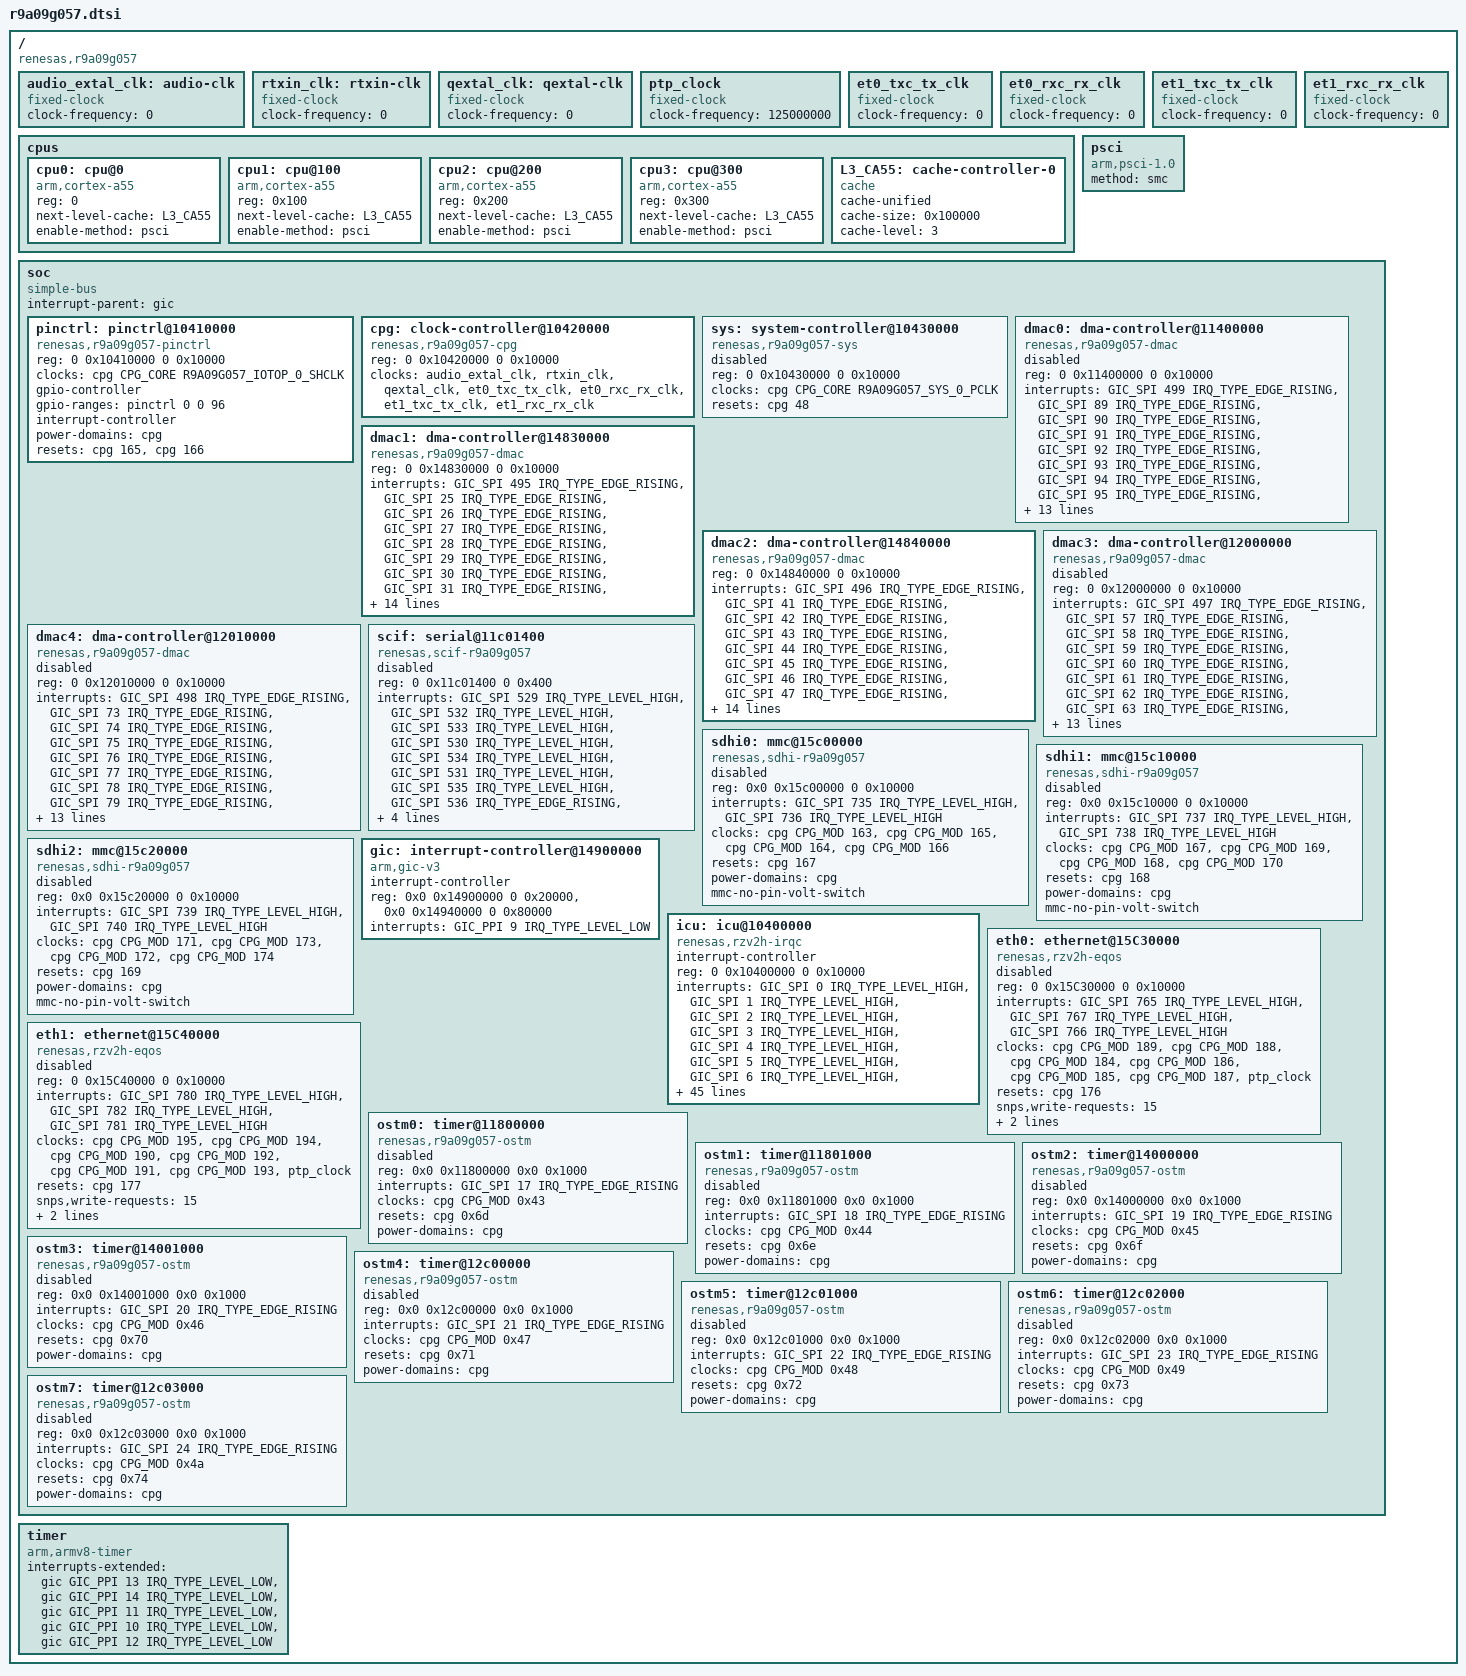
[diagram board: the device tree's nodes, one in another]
// SPDX-License-Identifier: (GPL-2.0-only OR BSD-2-Clause)
/*
 * Device Tree Source for the RZ/V2H SoC
 *
 * Copyright (C) 2024 Renesas Electronics Corp.
 */

#include <dt-bindings/clock/renesas,r9a09g057-cpg.h>
#include <dt-bindings/interrupt-controller/arm-gic.h>

/ {
	compatible = "renesas,r9a09g057";
	#address-cells = <2>;
	#size-cells = <2>;

	audio_extal_clk: audio-clk {
		compatible = "fixed-clock";
		#clock-cells = <0>;
		/* This value must be overridden by the board */
		clock-frequency = <0>;
	};

	rtxin_clk: rtxin-clk {
		compatible = "fixed-clock";
		#clock-cells = <0>;
		/* This value must be overridden by the board */
		clock-frequency = <0>;
	};

	qextal_clk: qextal-clk {
		compatible = "fixed-clock";
		#clock-cells = <0>;
		/* This value must be overridden by the board */
		clock-frequency = <0>;
	};

	/* ptp_clock input */
	ptp_clock: ptp_clock {
		compatible = "fixed-clock";
		#clock-cells = <0>;
		/* This value must be overridden by the board */
		clock-frequency = <125000000>;
	};

	/* et0_txc_tx_clk clock input */
	et0_txc_tx_clk: et0_txc_tx_clk {
		compatible = "fixed-clock";
		#clock-cells = <0>;
		/* This value must be overridden by the board */
		clock-frequency = <0>;
	};

	/* et0_rxc_rx_clk clock input */
	et0_rxc_rx_clk: et0_rxc_rx_clk {
		compatible = "fixed-clock";
		#clock-cells = <0>;
		/* This value must be overridden by the board */
		clock-frequency = <0>;
	};

	/* et1_txc_tx_clk clock input */
	et1_txc_tx_clk: et1_txc_tx_clk {
		compatible = "fixed-clock";
		#clock-cells = <0>;
		/* This value must be overridden by the board */
		clock-frequency = <0>;
	};

	/* et1_rxc_rx_clk clock input */
	et1_rxc_rx_clk: et1_rxc_rx_clk {
		compatible = "fixed-clock";
		#clock-cells = <0>;
		/* This value must be overridden by the board */
		clock-frequency = <0>;
	};

	cpus {
		#address-cells = <1>;
		#size-cells = <0>;

		cpu0: cpu@0 {
			compatible = "arm,cortex-a55";
			reg = <0>;
			device_type = "cpu";
			next-level-cache = <&L3_CA55>;
			enable-method = "psci";
		};

		cpu1: cpu@100 {
			compatible = "arm,cortex-a55";
			reg = <0x100>;
			device_type = "cpu";
			next-level-cache = <&L3_CA55>;
			enable-method = "psci";
		};

		cpu2: cpu@200 {
			compatible = "arm,cortex-a55";
			reg = <0x200>;
			device_type = "cpu";
			next-level-cache = <&L3_CA55>;
			enable-method = "psci";
		};

		cpu3: cpu@300 {
			compatible = "arm,cortex-a55";
			reg = <0x300>;
			device_type = "cpu";
			next-level-cache = <&L3_CA55>;
			enable-method = "psci";
		};

		L3_CA55: cache-controller-0 {
			compatible = "cache";
			cache-unified;
			cache-size = <0x100000>;
			cache-level = <3>;
		};
	};

	psci {
		compatible = "arm,psci-1.0", "arm,psci-0.2";
		method = "smc";
	};

	soc: soc {
		compatible = "simple-bus";
		interrupt-parent = <&gic>;
		#address-cells = <2>;
		#size-cells = <2>;
		ranges;

		pinctrl: pinctrl@10410000 {
			compatible = "renesas,r9a09g057-pinctrl";
			reg = <0 0x10410000 0 0x10000>;
			clocks = <&cpg CPG_CORE R9A09G057_IOTOP_0_SHCLK>;
			gpio-controller;
			#gpio-cells = <2>;
			gpio-ranges = <&pinctrl 0 0 96>;
			#interrupt-cells = <2>;
			interrupt-controller;
			power-domains = <&cpg>;
			resets = <&cpg 165>, <&cpg 166>;
		};

		cpg: clock-controller@10420000 {
			compatible = "renesas,r9a09g057-cpg";
			reg = <0 0x10420000 0 0x10000>;
			clocks = <&audio_extal_clk>, <&rtxin_clk>, <&qextal_clk>,
				 <&et0_txc_tx_clk>, <&et0_rxc_rx_clk>,
				 <&et1_txc_tx_clk>, <&et1_rxc_rx_clk>;
			clock-names = "audio_extal", "rtxin", "qextal",
				      "et0_txc_tx_clk", "et0_rxc_rx_clk",
				      "et1_txc_tx_clk", "et1_rxc_rx_clk";
			#clock-cells = <2>;
			#reset-cells = <1>;
			#power-domain-cells = <0>;
		};

		sys: system-controller@10430000 {
			compatible = "renesas,r9a09g057-sys";
			reg = <0 0x10430000 0 0x10000>;
			clocks = <&cpg CPG_CORE R9A09G057_SYS_0_PCLK>;
			resets = <&cpg 48>;
			status = "disabled";
		};

		dmac0: dma-controller@11400000 {
			compatible = "renesas,r9a09g057-dmac";
			reg = <0 0x11400000 0 0x10000>;
			interrupts = <GIC_SPI 499 IRQ_TYPE_EDGE_RISING>,
				     <GIC_SPI 89 IRQ_TYPE_EDGE_RISING>,
				     <GIC_SPI 90 IRQ_TYPE_EDGE_RISING>,
				     <GIC_SPI 91 IRQ_TYPE_EDGE_RISING>,
				     <GIC_SPI 92 IRQ_TYPE_EDGE_RISING>,
				     <GIC_SPI 93 IRQ_TYPE_EDGE_RISING>,
				     <GIC_SPI 94 IRQ_TYPE_EDGE_RISING>,
				     <GIC_SPI 95 IRQ_TYPE_EDGE_RISING>,
				     <GIC_SPI 96 IRQ_TYPE_EDGE_RISING>,
				     <GIC_SPI 97 IRQ_TYPE_EDGE_RISING>,
				     <GIC_SPI 98 IRQ_TYPE_EDGE_RISING>,
				     <GIC_SPI 99 IRQ_TYPE_EDGE_RISING>,
				     <GIC_SPI 100 IRQ_TYPE_EDGE_RISING>,
				     <GIC_SPI 101 IRQ_TYPE_EDGE_RISING>,
				     <GIC_SPI 102 IRQ_TYPE_EDGE_RISING>,
				     <GIC_SPI 103 IRQ_TYPE_EDGE_RISING>,
				     <GIC_SPI 104 IRQ_TYPE_EDGE_RISING>;
			interrupt-names = "error",
					  "ch0", "ch1", "ch2", "ch3",
					  "ch4", "ch5", "ch6", "ch7",
					  "ch8", "ch9", "ch10", "ch11",
					  "ch12", "ch13", "ch14", "ch15";
			clocks = <&cpg CPG_MOD 0>;
			power-domains = <&cpg>;
			resets = <&cpg 49>;
			#dma-cells = <1>;
			dma-channels = <16>;
			status = "disabled";
		};

		dmac1: dma-controller@14830000 {
			compatible = "renesas,r9a09g057-dmac";
			reg = <0 0x14830000 0 0x10000>;
			interrupts = <GIC_SPI 495 IRQ_TYPE_EDGE_RISING>,
				     <GIC_SPI 25 IRQ_TYPE_EDGE_RISING>,
				     <GIC_SPI 26 IRQ_TYPE_EDGE_RISING>,
				     <GIC_SPI 27 IRQ_TYPE_EDGE_RISING>,
				     <GIC_SPI 28 IRQ_TYPE_EDGE_RISING>,
				     <GIC_SPI 29 IRQ_TYPE_EDGE_RISING>,
				     <GIC_SPI 30 IRQ_TYPE_EDGE_RISING>,
				     <GIC_SPI 31 IRQ_TYPE_EDGE_RISING>,
				     <GIC_SPI 32 IRQ_TYPE_EDGE_RISING>,
				     <GIC_SPI 33 IRQ_TYPE_EDGE_RISING>,
				     <GIC_SPI 34 IRQ_TYPE_EDGE_RISING>,
				     <GIC_SPI 35 IRQ_TYPE_EDGE_RISING>,
				     <GIC_SPI 36 IRQ_TYPE_EDGE_RISING>,
				     <GIC_SPI 37 IRQ_TYPE_EDGE_RISING>,
				     <GIC_SPI 38 IRQ_TYPE_EDGE_RISING>,
				     <GIC_SPI 39 IRQ_TYPE_EDGE_RISING>,
				     <GIC_SPI 40 IRQ_TYPE_EDGE_RISING>;
			interrupt-names = "error",
					  "ch0", "ch1", "ch2", "ch3",
					  "ch4", "ch5", "ch6", "ch7",
					  "ch8", "ch9", "ch10", "ch11",
					  "ch12", "ch13", "ch14", "ch15";
			clocks = <&cpg 1>;
			power-domains = <&cpg>;
			resets = <&cpg 50>;
			#dma-cells = <1>;
			dma-channels = <16>;
			peripheral-request = <&icu 0>;
			status = "okay";
		};

		dmac2: dma-controller@14840000 {
			compatible = "renesas,r9a09g057-dmac";
			reg = <0 0x14840000 0 0x10000>;
			interrupts = <GIC_SPI 496 IRQ_TYPE_EDGE_RISING>,
				     <GIC_SPI 41 IRQ_TYPE_EDGE_RISING>,
				     <GIC_SPI 42 IRQ_TYPE_EDGE_RISING>,
				     <GIC_SPI 43 IRQ_TYPE_EDGE_RISING>,
				     <GIC_SPI 44 IRQ_TYPE_EDGE_RISING>,
				     <GIC_SPI 45 IRQ_TYPE_EDGE_RISING>,
				     <GIC_SPI 46 IRQ_TYPE_EDGE_RISING>,
				     <GIC_SPI 47 IRQ_TYPE_EDGE_RISING>,
				     <GIC_SPI 48 IRQ_TYPE_EDGE_RISING>,
				     <GIC_SPI 49 IRQ_TYPE_EDGE_RISING>,
				     <GIC_SPI 50 IRQ_TYPE_EDGE_RISING>,
				     <GIC_SPI 51 IRQ_TYPE_EDGE_RISING>,
				     <GIC_SPI 52 IRQ_TYPE_EDGE_RISING>,
				     <GIC_SPI 53 IRQ_TYPE_EDGE_RISING>,
				     <GIC_SPI 54 IRQ_TYPE_EDGE_RISING>,
				     <GIC_SPI 55 IRQ_TYPE_EDGE_RISING>,
				     <GIC_SPI 56 IRQ_TYPE_EDGE_RISING>;
			interrupt-names = "error",
					  "ch0", "ch1", "ch2", "ch3",
					  "ch4", "ch5", "ch6", "ch7",
					  "ch8", "ch9", "ch10", "ch11",
					  "ch12", "ch13", "ch14", "ch15";
			clocks = <&cpg CPG_MOD 2>;
			power-domains = <&cpg>;
			resets = <&cpg 51>;
			#dma-cells = <1>;
			dma-channels = <16>;
			peripheral-request = <&icu 1>;
			status = "okay";
		};

		dmac3: dma-controller@12000000 {
			compatible = "renesas,r9a09g057-dmac";
			reg = <0 0x12000000 0 0x10000>;
			interrupts = <GIC_SPI 497 IRQ_TYPE_EDGE_RISING>,
				     <GIC_SPI 57 IRQ_TYPE_EDGE_RISING>,
				     <GIC_SPI 58 IRQ_TYPE_EDGE_RISING>,
				     <GIC_SPI 59 IRQ_TYPE_EDGE_RISING>,
				     <GIC_SPI 60 IRQ_TYPE_EDGE_RISING>,
				     <GIC_SPI 61 IRQ_TYPE_EDGE_RISING>,
				     <GIC_SPI 62 IRQ_TYPE_EDGE_RISING>,
				     <GIC_SPI 63 IRQ_TYPE_EDGE_RISING>,
				     <GIC_SPI 64 IRQ_TYPE_EDGE_RISING>,
				     <GIC_SPI 65 IRQ_TYPE_EDGE_RISING>,
				     <GIC_SPI 66 IRQ_TYPE_EDGE_RISING>,
				     <GIC_SPI 67 IRQ_TYPE_EDGE_RISING>,
				     <GIC_SPI 68 IRQ_TYPE_EDGE_RISING>,
				     <GIC_SPI 69 IRQ_TYPE_EDGE_RISING>,
				     <GIC_SPI 70 IRQ_TYPE_EDGE_RISING>,
				     <GIC_SPI 71 IRQ_TYPE_EDGE_RISING>,
				     <GIC_SPI 72 IRQ_TYPE_EDGE_RISING>;
			interrupt-names = "error",
					  "ch0", "ch1", "ch2", "ch3",
					  "ch4", "ch5", "ch6", "ch7",
					  "ch8", "ch9", "ch10", "ch11",
					  "ch12", "ch13", "ch14", "ch15";
			clocks = <&cpg CPG_MOD 3>;
			power-domains = <&cpg>;
			resets = <&cpg 52>;
			#dma-cells = <1>;
			dma-channels = <16>;
			status = "disabled";
		};

		dmac4: dma-controller@12010000 {
			compatible = "renesas,r9a09g057-dmac";
			reg = <0 0x12010000 0 0x10000>;
			interrupts = <GIC_SPI 498 IRQ_TYPE_EDGE_RISING>,
				     <GIC_SPI 73 IRQ_TYPE_EDGE_RISING>,
				     <GIC_SPI 74 IRQ_TYPE_EDGE_RISING>,
				     <GIC_SPI 75 IRQ_TYPE_EDGE_RISING>,
				     <GIC_SPI 76 IRQ_TYPE_EDGE_RISING>,
				     <GIC_SPI 77 IRQ_TYPE_EDGE_RISING>,
				     <GIC_SPI 78 IRQ_TYPE_EDGE_RISING>,
				     <GIC_SPI 79 IRQ_TYPE_EDGE_RISING>,
				     <GIC_SPI 80 IRQ_TYPE_EDGE_RISING>,
				     <GIC_SPI 81 IRQ_TYPE_EDGE_RISING>,
				     <GIC_SPI 82 IRQ_TYPE_EDGE_RISING>,
				     <GIC_SPI 83 IRQ_TYPE_EDGE_RISING>,
				     <GIC_SPI 84 IRQ_TYPE_EDGE_RISING>,
				     <GIC_SPI 85 IRQ_TYPE_EDGE_RISING>,
				     <GIC_SPI 86 IRQ_TYPE_EDGE_RISING>,
				     <GIC_SPI 87 IRQ_TYPE_EDGE_RISING>,
				     <GIC_SPI 88 IRQ_TYPE_EDGE_RISING>;
			interrupt-names = "error",
					  "ch0", "ch1", "ch2", "ch3",
					  "ch4", "ch5", "ch6", "ch7",
					  "ch8", "ch9", "ch10", "ch11",
					  "ch12", "ch13", "ch14", "ch15";
			clocks = <&cpg 4>;
			power-domains = <&cpg>;
			resets = <&cpg 53>;
			#dma-cells = <1>;
			dma-channels = <16>;
			status = "disabled";
		};

		scif: serial@11c01400 {
			compatible = "renesas,scif-r9a09g057",
				     "renesas,scif-r9a07g044";
			reg = <0 0x11c01400 0 0x400>;
			interrupts = <GIC_SPI 529 IRQ_TYPE_LEVEL_HIGH>,
				     <GIC_SPI 532 IRQ_TYPE_LEVEL_HIGH>,
				     <GIC_SPI 533 IRQ_TYPE_LEVEL_HIGH>,
				     <GIC_SPI 530 IRQ_TYPE_LEVEL_HIGH>,
				     <GIC_SPI 534 IRQ_TYPE_LEVEL_HIGH>,
				     <GIC_SPI 531 IRQ_TYPE_LEVEL_HIGH>,
				     <GIC_SPI 535 IRQ_TYPE_LEVEL_HIGH>,
				     <GIC_SPI 536 IRQ_TYPE_EDGE_RISING>,
				     <GIC_SPI 537 IRQ_TYPE_EDGE_RISING>;
			interrupt-names = "eri", "rxi", "txi", "bri", "dri",
					  "tei", "tei-dri", "rxi-edge", "txi-edge";
			clocks = <&cpg CPG_MOD 143>;
			clock-names = "fck";
			power-domains = <&cpg>;
			resets = <&cpg 149>;
			status = "disabled";
		};

		sdhi0: mmc@15c00000  {
			compatible = "renesas,sdhi-r9a09g057";
			reg = <0x0 0x15c00000 0 0x10000>;
			interrupts = <GIC_SPI 735 IRQ_TYPE_LEVEL_HIGH>,
				     <GIC_SPI 736 IRQ_TYPE_LEVEL_HIGH>;
			clocks = <&cpg CPG_MOD 163>,
				 <&cpg CPG_MOD 165>,
				 <&cpg CPG_MOD 164>,
				 <&cpg CPG_MOD 166>;
			clock-names = "core", "clkh", "cd", "aclk";
			resets = <&cpg 167>;
			power-domains = <&cpg>;
			mmc-no-pin-volt-switch;
			status = "disabled";
		};

		sdhi1: mmc@15c10000 {
			compatible = "renesas,sdhi-r9a09g057";
			reg = <0x0 0x15c10000 0 0x10000>;
			interrupts = <GIC_SPI 737 IRQ_TYPE_LEVEL_HIGH>,
				     <GIC_SPI 738 IRQ_TYPE_LEVEL_HIGH>;
			clocks = <&cpg CPG_MOD 167>,
				 <&cpg CPG_MOD 169>,
				 <&cpg CPG_MOD 168>,
				 <&cpg CPG_MOD 170>;
			clock-names = "core", "clkh", "cd", "aclk";
			resets = <&cpg 168>;
			power-domains = <&cpg>;
			mmc-no-pin-volt-switch;
			status = "disabled";
		};

		sdhi2: mmc@15c20000 {
			compatible = "renesas,sdhi-r9a09g057";
			reg = <0x0 0x15c20000 0 0x10000>;
			interrupts = <GIC_SPI 739 IRQ_TYPE_LEVEL_HIGH>,
				     <GIC_SPI 740 IRQ_TYPE_LEVEL_HIGH>;
			clocks = <&cpg CPG_MOD 171>,
				 <&cpg CPG_MOD 173>,
				 <&cpg CPG_MOD 172>,
				 <&cpg CPG_MOD 174>;
			clock-names = "core", "clkh", "cd", "aclk";
			resets = <&cpg 169>;
			power-domains = <&cpg>;
			mmc-no-pin-volt-switch;
			status = "disabled";
		};

		gic: interrupt-controller@14900000 {
			compatible = "arm,gic-v3";
			#interrupt-cells = <3>;
			#address-cells = <0>;
			interrupt-controller;
			reg = <0x0 0x14900000 0 0x20000>,
			      <0x0 0x14940000 0 0x80000>;
			interrupts = <GIC_PPI 9 IRQ_TYPE_LEVEL_LOW>;
		};

		icu: icu@10400000 {
			compatible = "renesas,rzv2h-irqc";
			#interrupt-cells = <2>;
			#address-cells = <0>;
			interrupt-controller;
			reg = <0 0x10400000 0 0x10000>;
			interrupts = <GIC_SPI 0 IRQ_TYPE_LEVEL_HIGH>,
				     <GIC_SPI 1 IRQ_TYPE_LEVEL_HIGH>,
				     <GIC_SPI 2 IRQ_TYPE_LEVEL_HIGH>,
				     <GIC_SPI 3 IRQ_TYPE_LEVEL_HIGH>,
				     <GIC_SPI 4 IRQ_TYPE_LEVEL_HIGH>,
				     <GIC_SPI 5 IRQ_TYPE_LEVEL_HIGH>,
				     <GIC_SPI 6 IRQ_TYPE_LEVEL_HIGH>,
				     <GIC_SPI 7 IRQ_TYPE_LEVEL_HIGH>,
				     <GIC_SPI 8 IRQ_TYPE_LEVEL_HIGH>,
				     <GIC_SPI 9 IRQ_TYPE_LEVEL_HIGH>,
				     <GIC_SPI 10 IRQ_TYPE_LEVEL_HIGH>,
				     <GIC_SPI 11 IRQ_TYPE_LEVEL_HIGH>,
				     <GIC_SPI 12 IRQ_TYPE_LEVEL_HIGH>,
				     <GIC_SPI 13 IRQ_TYPE_LEVEL_HIGH>,
				     <GIC_SPI 14 IRQ_TYPE_LEVEL_HIGH>,
				     <GIC_SPI 15 IRQ_TYPE_LEVEL_HIGH>,
				     <GIC_SPI 16 IRQ_TYPE_LEVEL_HIGH>,
				     <GIC_SPI 419 IRQ_TYPE_LEVEL_HIGH>,
				     <GIC_SPI 420 IRQ_TYPE_LEVEL_HIGH>,
				     <GIC_SPI 421 IRQ_TYPE_LEVEL_HIGH>,
				     <GIC_SPI 422 IRQ_TYPE_LEVEL_HIGH>,
				     <GIC_SPI 423 IRQ_TYPE_LEVEL_HIGH>,
				     <GIC_SPI 424 IRQ_TYPE_LEVEL_HIGH>,
				     <GIC_SPI 425 IRQ_TYPE_LEVEL_HIGH>,
				     <GIC_SPI 426 IRQ_TYPE_LEVEL_HIGH>,
				     <GIC_SPI 427 IRQ_TYPE_LEVEL_HIGH>,
				     <GIC_SPI 428 IRQ_TYPE_LEVEL_HIGH>,
				     <GIC_SPI 429 IRQ_TYPE_LEVEL_HIGH>,
				     <GIC_SPI 430 IRQ_TYPE_LEVEL_HIGH>,
				     <GIC_SPI 431 IRQ_TYPE_LEVEL_HIGH>,
				     <GIC_SPI 432 IRQ_TYPE_LEVEL_HIGH>,
				     <GIC_SPI 433 IRQ_TYPE_LEVEL_HIGH>,
				     <GIC_SPI 434 IRQ_TYPE_LEVEL_HIGH>,
				     <GIC_SPI 435 IRQ_TYPE_LEVEL_HIGH>,
				     <GIC_SPI 436 IRQ_TYPE_LEVEL_HIGH>,
				     <GIC_SPI 437 IRQ_TYPE_LEVEL_HIGH>,
				     <GIC_SPI 438 IRQ_TYPE_LEVEL_HIGH>,
				     <GIC_SPI 439 IRQ_TYPE_LEVEL_HIGH>,
				     <GIC_SPI 440 IRQ_TYPE_LEVEL_HIGH>,
				     <GIC_SPI 441 IRQ_TYPE_LEVEL_HIGH>,
				     <GIC_SPI 442 IRQ_TYPE_LEVEL_HIGH>,
				     <GIC_SPI 443 IRQ_TYPE_LEVEL_HIGH>,
				     <GIC_SPI 444 IRQ_TYPE_LEVEL_HIGH>,
				     <GIC_SPI 445 IRQ_TYPE_LEVEL_HIGH>,
				     <GIC_SPI 446 IRQ_TYPE_LEVEL_HIGH>,
				     <GIC_SPI 447 IRQ_TYPE_LEVEL_HIGH>,
				     <GIC_SPI 448 IRQ_TYPE_LEVEL_HIGH>,
				     <GIC_SPI 449 IRQ_TYPE_LEVEL_HIGH>,
				     <GIC_SPI 450 IRQ_TYPE_LEVEL_HIGH>;
			clocks = <&cpg CPG_MOD 5>;
			clock-names = "pclk";
			power-domains = <&cpg>;
			resets = <&cpg 54>;
			status = "okay";
		};

		eth0: ethernet@15C30000 {
			compatible = "renesas,rzv2h-eqos",
					"snps,dwc-qos-ethernet-4.10";
			reg = <0 0x15C30000 0 0x10000>;
			interrupts = <GIC_SPI 765 IRQ_TYPE_LEVEL_HIGH>,
				     <GIC_SPI 767 IRQ_TYPE_LEVEL_HIGH>,
				     <GIC_SPI 766 IRQ_TYPE_LEVEL_HIGH>;
			interrupt-names = "macirq", "eth_wake_irq", "eth_lpi";
			clocks =  <&cpg CPG_MOD 189>,
				  <&cpg CPG_MOD 188>,
				  <&cpg CPG_MOD 184>,
				  <&cpg CPG_MOD 186>,
				  <&cpg CPG_MOD 185>,
				  <&cpg CPG_MOD 187>,
				  <&ptp_clock>;
			clock-names = "master_bus", "slave_bus", "tx",
				      "tx_180", "rx", "rx_180", "ptp_ref";
			resets = <&cpg 176>;
			#address-cells = <1>;
			#size-cells = <0>;
			status = "disabled";
			snps,write-requests = <15>;
			snps,read-requests = <15>;
			snps,burst-map = <0x7>;
		};

		eth1: ethernet@15C40000 {
			compatible = "renesas,rzv2h-eqos",
					"snps,dwc-qos-ethernet-4.10";
			reg = <0 0x15C40000 0 0x10000>;
			interrupts = <GIC_SPI 780 IRQ_TYPE_LEVEL_HIGH>,
				     <GIC_SPI 782 IRQ_TYPE_LEVEL_HIGH>,
				     <GIC_SPI 781 IRQ_TYPE_LEVEL_HIGH>;
			interrupt-names = "macirq", "eth_wake_irq", "eth_lpi";
			clocks =  <&cpg CPG_MOD 195>,
				  <&cpg CPG_MOD 194>,
				  <&cpg CPG_MOD 190>,
				  <&cpg CPG_MOD 192>,
				  <&cpg CPG_MOD 191>,
				  <&cpg CPG_MOD 193>,
				  <&ptp_clock>;
			clock-names = "master_bus", "slave_bus", "tx",
				      "tx_180", "rx", "rx_180", "ptp_ref";
			resets = <&cpg 177>;
			#address-cells = <1>;
			#size-cells = <0>;
			status = "disabled";
			snps,write-requests = <15>;
			snps,read-requests = <15>;
			snps,burst-map = <0x7>;
		};

		ostm0: timer@11800000 {
			compatible = "renesas,r9a09g057-ostm", "renesas,ostm";
			reg = <0x0 0x11800000 0x0 0x1000>;
			interrupts = <GIC_SPI 17 IRQ_TYPE_EDGE_RISING>;
			clocks = <&cpg CPG_MOD 0x43>;
			resets = <&cpg 0x6d>;
			power-domains = <&cpg>;
			status = "disabled";
		};

		ostm1: timer@11801000 {
			compatible = "renesas,r9a09g057-ostm", "renesas,ostm";
			reg = <0x0 0x11801000 0x0 0x1000>;
			interrupts = <GIC_SPI 18 IRQ_TYPE_EDGE_RISING>;
			clocks = <&cpg CPG_MOD 0x44>;
			resets = <&cpg 0x6e>;
			power-domains = <&cpg>;
			status = "disabled";
		};

		ostm2: timer@14000000 {
			compatible = "renesas,r9a09g057-ostm", "renesas,ostm";
			reg = <0x0 0x14000000 0x0 0x1000>;
			interrupts = <GIC_SPI 19 IRQ_TYPE_EDGE_RISING>;
			clocks = <&cpg CPG_MOD 0x45>;
			resets = <&cpg 0x6f>;
			power-domains = <&cpg>;
			status = "disabled";
		};

		ostm3: timer@14001000 {
			compatible = "renesas,r9a09g057-ostm", "renesas,ostm";
			reg = <0x0 0x14001000 0x0 0x1000>;
			interrupts = <GIC_SPI 20 IRQ_TYPE_EDGE_RISING>;
			clocks = <&cpg CPG_MOD 0x46>;
			resets = <&cpg 0x70>;
			power-domains = <&cpg>;
			status = "disabled";
		};

		ostm4: timer@12c00000 {
			compatible = "renesas,r9a09g057-ostm", "renesas,ostm";
			reg = <0x0 0x12c00000 0x0 0x1000>;
			interrupts = <GIC_SPI 21 IRQ_TYPE_EDGE_RISING>;
			clocks = <&cpg CPG_MOD 0x47>;
			resets = <&cpg 0x71>;
			power-domains = <&cpg>;
			status = "disabled";
		};

		ostm5: timer@12c01000 {
			compatible = "renesas,r9a09g057-ostm", "renesas,ostm";
			reg = <0x0 0x12c01000 0x0 0x1000>;
			interrupts = <GIC_SPI 22 IRQ_TYPE_EDGE_RISING>;
			clocks = <&cpg CPG_MOD 0x48>;
			resets = <&cpg 0x72>;
			power-domains = <&cpg>;
			status = "disabled";
		};

		ostm6: timer@12c02000 {
			compatible = "renesas,r9a09g057-ostm", "renesas,ostm";
			reg = <0x0 0x12c02000 0x0 0x1000>;
			interrupts = <GIC_SPI 23 IRQ_TYPE_EDGE_RISING>;
			clocks = <&cpg CPG_MOD 0x49>;
			resets = <&cpg 0x73>;
			power-domains = <&cpg>;
			status = "disabled";
		};

		ostm7: timer@12c03000 {
			compatible = "renesas,r9a09g057-ostm", "renesas,ostm";
			reg = <0x0 0x12c03000 0x0 0x1000>;
			interrupts = <GIC_SPI 24 IRQ_TYPE_EDGE_RISING>;
			clocks = <&cpg CPG_MOD 0x4a>;
			resets = <&cpg 0x74>;
			power-domains = <&cpg>;
			status = "disabled";
		};
	};

	timer {
		compatible = "arm,armv8-timer";
		interrupts-extended = <&gic GIC_PPI 13 IRQ_TYPE_LEVEL_LOW>,
				      <&gic GIC_PPI 14 IRQ_TYPE_LEVEL_LOW>,
				      <&gic GIC_PPI 11 IRQ_TYPE_LEVEL_LOW>,
				      <&gic GIC_PPI 10 IRQ_TYPE_LEVEL_LOW>,
				      <&gic GIC_PPI 12 IRQ_TYPE_LEVEL_LOW>;
		interrupt-names = "sec-phys", "phys", "virt", "hyp-phys", "hyp-virt";
	};
};
